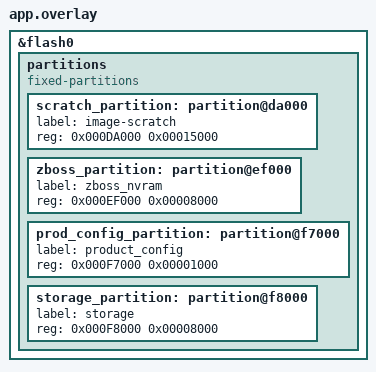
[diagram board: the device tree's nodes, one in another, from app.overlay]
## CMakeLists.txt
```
#
# Copyright (c) 2020 Nordic Semiconductor ASA
#
# SPDX-License-Identifier: LicenseRef-Nordic-5-Clause
#

cmake_minimum_required(VERSION 3.20.0)

# Stub for ZBOSS callout
add_compile_definitions(zb_nvram_erase_finished=zb_nvram_erase_finished_stub)

find_package(Zephyr REQUIRED HINTS $ENV{ZEPHYR_BASE})

project(zigbee_osif_nvram_test)

target_sources(app PRIVATE
  src/main.c
)
```

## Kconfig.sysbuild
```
#
# Copyright (c) 2024 Nordic Semiconductor
#
# SPDX-License-Identifier: LicenseRef-Nordic-5-Clause
#

source "${ZEPHYR_BASE}/share/sysbuild/Kconfig"

config NRF_DEFAULT_IPC_RADIO
	default y

config NETCORE_IPC_RADIO_IEEE802154
	default y
```

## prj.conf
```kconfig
#
# Copyright (c) 2019-2023 Nordic Semiconductor ASA
#
# SPDX-License-Identifier: LicenseRef-Nordic-5-Clause
#

CONFIG_ZTEST=y
CONFIG_FLASH=y
CONFIG_FLASH_PAGE_LAYOUT=y
CONFIG_FLASH_MAP=y
CONFIG_MPU_ALLOW_FLASH_WRITE=y

CONFIG_ZIGBEE=y
CONFIG_ZIGBEE_ROLE_COORDINATOR=y

CONFIG_CRYPTO=y
CONFIG_CRYPTO_NRF_ECB=y
CONFIG_CRYPTO_INIT_PRIORITY=80

# Networking
CONFIG_NET_IPV6=n
CONFIG_NET_IP_ADDR_CHECK=n
CONFIG_NET_UDP=n
```

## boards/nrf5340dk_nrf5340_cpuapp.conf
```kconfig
#
# Copyright (c) 2022 Nordic Semiconductor ASA
#
# SPDX-License-Identifier: LicenseRef-Nordic-5-Clause
#

CONFIG_MAIN_STACK_SIZE=2048

# Use software cryptography on nRF5340
CONFIG_CRYPTO=n
CONFIG_CRYPTO_NRF_ECB=n
CONFIG_TINYCRYPT=y
CONFIG_CTR_DRBG_CSPRNG_GENERATOR=y
CONFIG_ZIGBEE_USE_SOFTWARE_AES=y
CONFIG_ENTROPY_CC3XX=y

# Networking
CONFIG_MPSL=n
```

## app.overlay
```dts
/* Copyright (c) 2019 Nordic Semiconductor ASA
 *
 * SPDX-License-Identifier: Apache-2.0
 */

/delete-node/ &scratch_partition;
/delete-node/ &storage_partition;

&flash0 {
	partitions {
		compatible = "fixed-partitions";
		#address-cells = <1>;
		#size-cells = <1>;

		scratch_partition: partition@da000 {
			label = "image-scratch";
			reg = <0x000DA000 0x00015000>;
		};
		zboss_partition: partition@ef000 {
			label = "zboss_nvram";
			reg = <0x000EF000 0x00008000>;
		};
		prod_config_partition: partition@f7000 {
			label = "product_config";
			reg = <0x000F7000 0x00001000>;
		};
		storage_partition: partition@f8000 {
			label = "storage";
			reg = <0x000F8000 0x00008000>;
		};
	};
};
```

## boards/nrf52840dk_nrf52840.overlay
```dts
/*
 * Copyright (c) 2020 Nordic Semiconductor ASA
 *
 * SPDX-License-Identifier: LicenseRef-Nordic-5-Clause
 */

/ {
	chosen {
		zephyr,entropy = &rng;
	};
};
```

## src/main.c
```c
/*
 * Copyright (c) 2019 Nordic Semiconductor ASA
 *
 * SPDX-License-Identifier: LicenseRef-Nordic-5-Clause
 */

#include <zephyr/ztest.h>
#include <pm_config.h>
#include <zboss_api.h>
#include <zb_errors.h>
#include <zb_osif.h>

#define PAGE_SIZE 0x400         /* Size for testing purpose */

#define ZBOSS_NVRAM_PAGE_SIZE (PM_ZBOSS_NVRAM_SIZE / CONFIG_ZIGBEE_NVRAM_PAGE_COUNT)

#define PHYSICAL_PAGE_SIZE 0x1000 /* For nvram in nrf5 products */

BUILD_ASSERT((ZBOSS_NVRAM_PAGE_SIZE % PHYSICAL_PAGE_SIZE) == 0,
	     "The size must be a multiply of physical page size.");

static uint8_t zb_nvram_buf[PAGE_SIZE];

/* Stub for ZBOSS callout */
void zb_nvram_erase_finished_stub(zb_uint8_t page)
{
}

/* Stub for ZBOSS signal handler */
void zboss_signal_handler(zb_bufid_t bufid)
{
}

static void test_case_setup(void *f)
{
	ARG_UNUSED(f);

	/* Erase NVRAM to have repeatability of test runs. */
	for (int page = 0; page < CONFIG_ZIGBEE_NVRAM_PAGE_COUNT; page++) {
		int ret = zb_osif_nvram_erase_async(page);

		zassert_true(ret == RET_OK, "Erasing failed");
	}
}

ZTEST_SUITE(osif_test, NULL, NULL, test_case_setup, NULL, NULL);

ZTEST(osif_test, test_zb_nvram_memory_size)
{
	zassert_true(zb_get_nvram_page_length() == ZBOSS_NVRAM_PAGE_SIZE,
		     "Page size fail");

	zassert_true(zb_get_nvram_page_count() == CONFIG_ZIGBEE_NVRAM_PAGE_COUNT,
		     "Page count fail");
}

ZTEST(osif_test, test_zb_nvram_erase)
{
	for (int page = 0; page < CONFIG_ZIGBEE_NVRAM_PAGE_COUNT; page++) {
		int ret = zb_osif_nvram_erase_async(page);

		zassert_true(ret == RET_OK, "Erasing failed");
	}

	/* Validate if flash memory is cleared */
	for (uint8_t page = 0; page < CONFIG_ZIGBEE_NVRAM_PAGE_COUNT; page++) {

		/* Validate all physical page offsets */
		for (uint32_t offset = 0; offset < ZBOSS_NVRAM_PAGE_SIZE;
		     offset += PHYSICAL_PAGE_SIZE) {

			zb_osif_nvram_read(page, offset, zb_nvram_buf,
					   PAGE_SIZE);
			for (int i = 0; i < PAGE_SIZE; i++) {
				zassert_true(zb_nvram_buf[i] == 0xFF,
					     "Erasing failed");
			}
		}
	}
}

ZTEST(osif_test, test_zb_nvram_write)
{
	const uint8_t MEM_PATTERN = 0xAA;

	memset(zb_nvram_buf, MEM_PATTERN, sizeof(zb_nvram_buf));

	for (uint8_t page = 0; page < CONFIG_ZIGBEE_NVRAM_PAGE_COUNT; page++) {

		/* Write to all physical page offsets */
		for (uint32_t offset = 0; offset < ZBOSS_NVRAM_PAGE_SIZE;
		     offset += PHYSICAL_PAGE_SIZE) {

			int ret = zb_osif_nvram_write(page, offset,
						      zb_nvram_buf,
						      PAGE_SIZE);

			zassert_true(ret == RET_OK, "writing failed");

			/* Validate write operation */
			zb_osif_nvram_read(page,
					   offset,
					   zb_nvram_buf,
					   PAGE_SIZE);
			for (int i = 0; i < PAGE_SIZE; i++) {
				zassert_true(zb_nvram_buf[i] == MEM_PATTERN,
					     "writing failed");
			}
		}
	}
}
```
